# nrf54h20_engb_secure register map
Vendor: Nordic Semiconductor; Series: nRF54h; File version: 1
CPU: CM33 r0p4, little endian, MPU, no FPU, 3 interrupt priority bits, 480 interrupts, 8 SAU regions
Registers are 32-bit, read-write, reset 0x0 unless marked. A register's access mark holds for its fields unless they carry their own. Offsets are from the block's base; [hi:lo] are bit positions; lines under a group give offsets from that group; {n}, {i} and the like mark numbered series; 'fields as' and 'values as' point back to an identical list.

## SICR_S — Secure Information Configuration Registers
Base 0x0E000000
0x00 IROT group — Information on immutable Root of Trust. Secure domain ROM writes these registers only in LCS Empty, RoT and DEPLOYED.
  0x00 SYSROM group — 32-bit base revision of SysCtrl ROM and upto eight patch revisions.
    0x00 BASE — 32-bit revision of base revision of SysCtrl ROM.
      [31:0] VERSION — Base revision.
    {0x4+4k} PATCH[{k}] (k=0..7) — Description collection: 32-bit revision of utpo n patches.
      [31:0] VERSION — nth patch revision.
        0xFFFFFFFF=UnPatched (No patch applied.)
  0x24 SECROM group — 32-bit revision of Secure Domain ROM base version and utpo sixteen patch versions.
    0x00 BASE — 32-bit revision of base revision of Secure domain ROM.
      [31:0] VERSION — Base revision.
    {0x4+4k} PATCH[{k}] (k=0..15) — Description collection: 32-bit revision of utpo n patches.
      fields as IROT.SYSROM.PATCH[0]
  {0x70+4j} DEVICEID[{j}] (j=0..3) — Description collection: 128-bit UUID as Device Id.
    [0] UUID — Device UUID [n]. The DEVICE.UUID[0] contains the least significant bits of the device identifier.
  0x80 UCODE — 32-bit revision of the CRACEN uCode.
    [0] VALUE — 32-bit revision of CRACEN uCode.
  0x84 LCS1 group — LCS reported here shall be indentical to the oe in LCS2.
    0x00 LCS — The device lifecycle state as determined by the secure domain ROM code.
      [31:0] STATE — The device lifecycle state.
        0x1000=Empty (LCS is EMPTY, device assets are installed in this state.); 0x2000=RoT (Updatable RoT is installed and is verified by the immutable RoT.); 0x3000=Deployed (Similar to LCS RoT, with device certificate installed.)
  0x88 LCS2 group — LCS reported here shall be indentical to the oe in LCS1.
    0x00 LCS — The device lifecycle state as determined by the secure domain ROM code.
      fields as IROT.LCS1.LCS
  0x8C BOOTSTATUS — Indicates if the device is booted in Safe Mode.
    [31:0] STATUS — Status of boot.
      0xFFFFFFFF=NormalMode; 0xA2659BE7=Safe Mode with limited access to system resources; 0xDEB609E4=Authdbg_NormalMode (Authenticated debug session in Normal Mode.); 0xDEB67AFE=Authdbg_SafeMode (Authenticated debug session in Safe Mode.)
0xF0 UROT group — Interface to store information related to the updateable RoT.
  0x00 SM group — Signed Manifest verified by the Secure Domain ROM Code to establish the primary RoT.
    0x00 TBS group — Manifest describing the secure domain firmware. The secure domain ROM code verifies the signature on the digest of this register.
      0x00 PUBKEY group — Raw public key used to verify the signed manifest.
        0x00 SIZE — The size of the raw public key(in bytes).
          [31:0] SIZE — Key size
            0xFFFFFFFF=Unprogrammed (The key is not programmed.); 32=SizeEd25519 (The size of the raw Ed25519 public key. Currently this is the only size supported by the secure domain ROM code.)
        0x04 ADDR — Address of the raw public key.
          [31:0] ADDR — Public key address.
            0xFFFFFFFF=Unprogrammed (The key is not programmed.)
      0x08 LAYOUT group — The MRAM layout of UROT firmware and the recovery image.
        0x00 USLOT group — Start adddress and max size of UROT slot (USLOT), Shall remain the same for firmware updates once programmed or unless transitioned back to LCS Empty.
          0x00 START — Start address of the UROT firmware. Shall not overlap with the recovery slot (RSLOT).
            [31:0] ADDR
              0xFFFFFFFF=Undefined (The slot is not defined.)
          0x04 MAX — Maximum size of the UROT firmware in bytes.
            [31:0] SIZE
              0xFFFFFFFF=Undefined (The slot is not defined.)
        0x08 RSLOT group — Start adddress and max size of recovery slot (RSLOT), Shall remain the same for firmware updates once programmed or unless transitioned back to LCS Empty.
          0x00 START — Start address of the recovery firmware. Shall not overlap with the UROT slot(USLOT).
            [31:0] ADDR
              0xFFFFFFFF=Undefined (The slot is not defined.)
          0x04 MAX — Maximum size of the recovery image in bytes.
            [31:0] SIZE
              0xFFFFFFFF=Undefined (The slot is not defined.)
      0x18 FW group — FW verified by the secure domain ROM code.
        0x00 SIZE — The firmware size (in bytes). Shall not exceed the max defined limits for USLOT in case of UROT firmware.Shall not exceed the max defined limits for USLOT in case of UROT firmware.
          [31:0] SIZE — Firmware size
            0xFFFFFFFF=Unprogrammed (The FW is not programmed.)
        0x04 ADDR — Address of the firmware verified by the secure domain ROM code.
          [31:0] ADDR — Firmware address
            0xFFFFFFFF=Unprogrammed (The FW is not programmed.)
        {0x8+4m} DIGEST[{m}] (m=0..15) — Description collection: SHA2-512 digest of the firmware.
          [31:0] VALUE — SHA2-512 Digest value
            0xFFFFFFFF=Unprogrammed (The FW digest, and hence the FW is not programmed.)
        {0x48+4m} VERSION[{m}] (m=0..3) — Description collection: 128-bit revision of the firmware; can be left Unprogrammed.
          [0] VALUE — nth word of the version.
        0x58 TIMESTAMP — Unsigned 32-bit integer timestamp of the firmware in Unix time used to prevent downgrade of firmware on firmware update.
          [31:0] VALUE — Unsigned unix-time timestamp of the firmware
            0xFFFFFFFF=Unprogrammed (The FW timestamp is not programmed.)
        0x5C PARTNO — Part-number for which the firmware is built. Must match the part number in OICR region.
          [31:0] VALUE — Part number of the device for which the firmware is built.
            0xFFFFFFFF=Unprogrammed (The part number is not programmed.)
      0x78 POLICY group — Set various policies on related to the firmware verification and update.
        0x00 UPDATE — Enable or Disable firmware update.
          [31:0] ENABLE — Possible values for this register.
            0xFFFFFFFF=Unprogrammed (The policy is not programmed, hence any existing policy on update is left unchanged.); 0xC3965A5A=Enabled (Enable firmware update.); 0x47D13CA5=Disabled (Disable firmware update.)
        0x04 REVOKE — Configure key revocation policy.
          [31:0] ENABLE — Possible values for this register
            0xFFFFFFFF=Unprogrammed (The policy is not programmed, hence any existing policy on auto-revocation is left unchanged.); 0xC3965A5A=Enabled (Enable auto-revocation of keys.); 0x47D13CA5=Disabled (Disable auto-revocation of keys used to verify firmware.)
        0x08 DGPREV — Configure the downgrade prevention policy.
          [31:0] ENABLE — Possible values for this register
            0xFFFFFFFF=Unprogrammed (The policy is not programmed, hence any existing policy on downgrade prevention is unaltered.); 0xC3965A5A=Enable downgrade protection on firmware update. If Enabled, the SM.TBS.FW.TIMESTAMP register cannot be left Unprogrammed.; 0x47D13CA5=Disable downgrade protection on firmware updates. If Disabled, the SM.TBS.FW.TIMESTAMP register shall be left Unprogrammed.
        {0xC+4m} RFU[{m}] (m=0..4) — Description collection: These registers are included when generating signature of the TBS content of SM.
      {0x98+4l} CIPHERDIGEST[{l}] (l=0..15) — Description collection: SHA2-512 digest of the AES-GCM AAD, IV and encrypted firmware.
        [31:0] VALUE — SHA2-512 Digest value
          0xFFFFFFFF=Unprogrammed (Encrypted firmware digest, unprogrammed if the FW is not programmed.)
      {0xD8+4l} RFU[{l}] (l=0..3) — Description collection: These registers are included when generating signature of the TBS content of SM
    0xF4 SIGNATURE group — Signature on the manifest defined in TBS
      0x00 ALG — The signature algorithm identifier as defined in RFC8152.
        [31:0] ID — Algorithm identifier
          0xFFFFFFFF=Unprogrammed (The signature algorithm identifier is not programmed.); 5=AlgIdEd25519 (ARM ADAC-defined identifier for Ed25519. The use of ARM ADAC-defined identifier ensures consistent user interface on CTRL-AP and SICR. Only Ed25519 curve is supported.)
      0x04 SIZE — Size of the raw signature in bytes.
        [31:0] SIZE — Signature size
          0xFFFFFFFF=Unprogrammed (The signature is not programmed.); 64=SizeEd25519 (Size of Ed25519 signature bytestring.); 64=MaxSize (Currently, the secure domain ROM code supports only Ed25519 (and only Ed25519 curve) signature scheme, and hence the MaxSize is the same as the Ed25519 signature size.)
      0x08 ADDR — Address of the signature on the firmware manifest.
        [31:0] ADDR — Signature address.
          0xFFFFFFFF=Unprogrammed (The signature is not programmed.)
  0x100 RECOVERY group — Signed manifest of the recovery firmware.
    0x00 SM group — Signed Manifest verified by the Secure Domain ROM Code to establish the primary RoT.
      0x00 TBS group — Manifest describing the secure domain firmware. The secure domain ROM code verifies the signature on the digest of this register.
        0x00 PUBKEY group — Raw public key used to verify the signed manifest.
          0x00 SIZE — The size of the raw public key(in bytes).
            fields as UROT.SM.TBS.PUBKEY.SIZE
          0x04 ADDR — Address of the raw public key.
            fields as UROT.SM.TBS.PUBKEY.ADDR
        0x08 LAYOUT group — The MRAM layout of UROT firmware and the recovery image.
          0x00 USLOT group — Start adddress and max size of UROT slot (USLOT), Shall remain the same for firmware updates once programmed or unless transitioned back to LCS Empty.
            0x00 START — Start address of the UROT firmware. Shall not overlap with the recovery slot (RSLOT).
              [31:0] ADDR
                0xFFFFFFFF=Undefined (The slot is not defined.)
            0x04 MAX — Maximum size of the UROT firmware in bytes.
              [31:0] SIZE
                0xFFFFFFFF=Undefined (The slot is not defined.)
          0x08 RSLOT group — Start adddress and max size of recovery slot (RSLOT), Shall remain the same for firmware updates once programmed or unless transitioned back to LCS Empty.
            0x00 START — Start address of the recovery firmware. Shall not overlap with the UROT slot(USLOT).
              [31:0] ADDR
                0xFFFFFFFF=Undefined (The slot is not defined.)
            0x04 MAX — Maximum size of the recovery image in bytes.
              [31:0] SIZE
                0xFFFFFFFF=Undefined (The slot is not defined.)
        0x18 FW group — FW verified by the secure domain ROM code.
          0x00 SIZE — The firmware size (in bytes). Shall not exceed the max defined limits for USLOT in case of UROT firmware.Shall not exceed the max defined limits for USLOT in case of UROT firmware.
            fields as UROT.SM.TBS.FW.SIZE
          0x04 ADDR — Address of the firmware verified by the secure domain ROM code.
            fields as UROT.SM.TBS.FW.ADDR
          {0x8+4p} DIGEST[{p}] (p=0..15) — Description collection: SHA2-512 digest of the firmware.
            fields as UROT.SM.TBS.FW.DIGEST[0]
          {0x48+4p} VERSION[{p}] (p=0..3) — Description collection: 128-bit revision of the firmware; can be left Unprogrammed.
            [0] VALUE — nth word of the version.
          0x58 TIMESTAMP — Unsigned 32-bit integer timestamp of the firmware in Unix time used to prevent downgrade of firmware on firmware update.
            fields as UROT.SM.TBS.FW.TIMESTAMP
          0x5C PARTNO — Part-number for which the firmware is built. Must match the part number in OICR region.
            fields as UROT.SM.TBS.FW.PARTNO
        0x78 POLICY group — Set various policies on related to the firmware verification and update.
          0x00 UPDATE — Enable or Disable firmware update.
            fields as UROT.SM.TBS.POLICY.UPDATE
          0x04 REVOKE — Configure key revocation policy.
            fields as UROT.SM.TBS.POLICY.REVOKE
          0x08 DGPREV — Configure the downgrade prevention policy.
            fields as UROT.SM.TBS.POLICY.DGPREV
          {0xC+4p} RFU[{p}] (p=0..4) — Description collection: These registers are included when generating signature of the TBS content of SM.
        {0x98+4m} CIPHERDIGEST[{m}] (m=0..15) — Description collection: SHA2-512 digest of the AES-GCM AAD, IV and encrypted firmware.
          fields as UROT.SM.TBS.CIPHERDIGEST[0]
        {0xD8+4m} RFU[{m}] (m=0..3) — Description collection: These registers are included when generating signature of the TBS content of SM
      0xF4 SIGNATURE group — Signature on the manifest defined in TBS
        0x00 ALG — The signature algorithm identifier as defined in RFC8152.
          fields as UROT.SM.SIGNATURE.ALG
        0x04 SIZE — Size of the raw signature in bytes.
          fields as UROT.SM.SIGNATURE.SIZE
        0x08 ADDR — Address of the signature on the firmware manifest.
          fields as UROT.SM.SIGNATURE.ADDR
  0x200 UPDATE group — Description of FW Updates, if any. In case, SICR.UROT.TBS.POLICY.UPDATE is set to Disabled, these registers are ignored by the secure domain ROM code.
    0x00 OPERATION — Command from the secure domain firmware to the secure domain ROM code.
      [31:0] OPCODE — Opcode to identify the command.
        0xFFFFFFFF=Nop (No operation pending.); 0x80000001=UROTVerify (Command to only verify UROT (plain-text or encrypted) firmware update without applying it.); 0x80000002=UROTActivate (Command to verify and update encrypted UROT firmware.); 0x80000003=RecoveryVerify (Command to verify the recovery (plain-text only) firmware update without applying it.); 0x80000004=RecoveryActivate (Command to verify and update plain-text Recovery firmware.); 0x80000005=UROTPlainTextActivate (Command to verify and update plain-text UROT firmware.); 0xA0000001=AROTRecovery (Instructs the ROM code to boot the recovery image in safe mode to download a AROT image instead of a UROT image.)
    0x04 STATUS — ROM code indicates the status of update to the secure domain firmware via this register.
      [31:0] CODE — Status code.
        0xFFFFFFFF=None (No operation pending to indicate any status.); 0xF0000001=UnknownOperation (Unknown OPCODE in SICR.UROT.UPDATE.OPERATION.); 0xF0000002=InvalidManifest (The information in the manifest is invalid.); 0xF0000003=StaleFW (The timestamp on the firmware is older than the current one.); 0xF0000005=VerifyFailure (The signature did not verify.); 0xF0000006=VerifyOK (Signature verification is successful.); 0xF0000007=UROTUpdateDisabled (UROT firmware update is disabled via policy.); 0xF0000008=UROTActivated (UROT firmware update verification and installation succeeded.); 0xF0000009=RecoveryActivated (Recovery firmware update verification and installation succeeded.); 0xF000000A=RecoveryUpdateDisabled (Recovery update is disabled via policy.); 0xF1000000=AROTRecovery (Recovery image is booted so that the recovery image can download a AROT image that ROM does not verify.)
    0x08 DOWNLOAD group — Information about downloaded firmware update. The addresses described here are the location of the update and not the location they must be installed. The installation information is described in the signed manifest.
      0x00 FW — Location for the firmware update to be installed.
        [31:0] ADDR — The MRAM Location of the firmware to be installed. This is not the same as the address in the signed manifest. The signed manifest contains the target location where the firmware must be installed, not the current location where it is downloaded.
          0xFFFFFFFF=Unprogrammed (The signature is not programmed.)
      0x04 PUBKEY — Location of the public key to verify the signature on the firmware update.
        [31:0] ADDR — MRAM Location for the signature on the firmware update. This is not the same as the address in the signed manifest. The signed manifest contains the target location where the public key must be kept once the update is installed, not the current location where it is downloaded.
          0xFFFFFFFF=Unprogrammed (The signature is not programmed.)
      0x08 SIGNATURE — Location for the signature on the firmware update to be verified before the update is installed.
        [31:0] ADDR — MRAM Location for the signature on the firmware update. This is not the same as the address in the signed manifest. The signed manifest contains the target location where the signature must be kept once the update is installed, not the current location where it is downloaded.
          0xFFFFFFFF=Unprogrammed (The signature is not programmed.)
      0x0C MAX — Max Size of the download.
        [31:0] SIZE — Max size of the downloaded firmware update. This define is ignored during update of UROT or the recovery image since the signed manifest contains the needed sizes. This field is used to define the writable MRAM region when the recovery image is started in the safe mode.
          0xFFFFFFFF=Unprogrammed (The signature is not programmed.)
    0x20 SM group — Signed Manifest verified by the Secure Domain ROM Code to establish the primary RoT.
      0x00 TBS group — Manifest describing the secure domain firmware. The secure domain ROM code verifies the signature on the digest of this register.
        0x00 PUBKEY group — Raw public key used to verify the signed manifest.
          0x00 SIZE — The size of the raw public key(in bytes).
            fields as UROT.SM.TBS.PUBKEY.SIZE
          0x04 ADDR — Address of the raw public key.
            fields as UROT.SM.TBS.PUBKEY.ADDR
        0x08 LAYOUT group — The MRAM layout of UROT firmware and the recovery image.
          0x00 USLOT group — Start adddress and max size of UROT slot (USLOT), Shall remain the same for firmware updates once programmed or unless transitioned back to LCS Empty.
            0x00 START — Start address of the UROT firmware. Shall not overlap with the recovery slot (RSLOT).
              [31:0] ADDR
                0xFFFFFFFF=Undefined (The slot is not defined.)
            0x04 MAX — Maximum size of the UROT firmware in bytes.
              [31:0] SIZE
                0xFFFFFFFF=Undefined (The slot is not defined.)
          0x08 RSLOT group — Start adddress and max size of recovery slot (RSLOT), Shall remain the same for firmware updates once programmed or unless transitioned back to LCS Empty.
            0x00 START — Start address of the recovery firmware. Shall not overlap with the UROT slot(USLOT).
              [31:0] ADDR
                0xFFFFFFFF=Undefined (The slot is not defined.)
            0x04 MAX — Maximum size of the recovery image in bytes.
              [31:0] SIZE
                0xFFFFFFFF=Undefined (The slot is not defined.)
        0x18 FW group — FW verified by the secure domain ROM code.
          0x00 SIZE — The firmware size (in bytes). Shall not exceed the max defined limits for USLOT in case of UROT firmware.Shall not exceed the max defined limits for USLOT in case of UROT firmware.
            fields as UROT.SM.TBS.FW.SIZE
          0x04 ADDR — Address of the firmware verified by the secure domain ROM code.
            fields as UROT.SM.TBS.FW.ADDR
          {0x8+4p} DIGEST[{p}] (p=0..15) — Description collection: SHA2-512 digest of the firmware.
            fields as UROT.SM.TBS.FW.DIGEST[0]
          {0x48+4p} VERSION[{p}] (p=0..3) — Description collection: 128-bit revision of the firmware; can be left Unprogrammed.
            [0] VALUE — nth word of the version.
          0x58 TIMESTAMP — Unsigned 32-bit integer timestamp of the firmware in Unix time used to prevent downgrade of firmware on firmware update.
            fields as UROT.SM.TBS.FW.TIMESTAMP
          0x5C PARTNO — Part-number for which the firmware is built. Must match the part number in OICR region.
            fields as UROT.SM.TBS.FW.PARTNO
        0x78 POLICY group — Set various policies on related to the firmware verification and update.
          0x00 UPDATE — Enable or Disable firmware update.
            fields as UROT.SM.TBS.POLICY.UPDATE
          0x04 REVOKE — Configure key revocation policy.
            fields as UROT.SM.TBS.POLICY.REVOKE
          0x08 DGPREV — Configure the downgrade prevention policy.
            fields as UROT.SM.TBS.POLICY.DGPREV
          {0xC+4p} RFU[{p}] (p=0..4) — Description collection: These registers are included when generating signature of the TBS content of SM.
        {0x98+4m} CIPHERDIGEST[{m}] (m=0..15) — Description collection: SHA2-512 digest of the AES-GCM AAD, IV and encrypted firmware.
          fields as UROT.SM.TBS.CIPHERDIGEST[0]
        {0xD8+4m} RFU[{m}] (m=0..3) — Description collection: These registers are included when generating signature of the TBS content of SM
      0xF4 SIGNATURE group — Signature on the manifest defined in TBS
        0x00 ALG — The signature algorithm identifier as defined in RFC8152.
          fields as UROT.SM.SIGNATURE.ALG
        0x04 SIZE — Size of the raw signature in bytes.
          fields as UROT.SM.SIGNATURE.SIZE
        0x08 ADDR — Address of the signature on the firmware manifest.
          fields as UROT.SM.SIGNATURE.ADDR
  {0x320+4j} CERTIFICATE[{j}] (j=0..1023) — Description collection: Device X.509 certificate.
    [0] CERT — Device certificate.
0x1500 AROT group — Interface used by the secure domain firmware to extend the RoT to the other local domains and store information on configuration of debug access ports, CTRL-AP methods, and other platfrom security related configurations per domain. These registers are only accessed the secure domain firmware. Any operations related to the local domains must be requested via the secure domain firmware API.
  0x00 SECURE group — Unspecified
    {0x0+0x60*k} OEMPUBKEY[{k}] (k=0..2) group — The public key used by the top level SUIT manifest. The public key is stored as additional authenticated data (AAD) in unencrypted form using an AEAD scheme realized by AES-256 GCM mode, with the secure domain KEK used as a secret key. The initialization vector is provided in NONCE register. Key attributes from ATTR register shall be used as an additional authenticated data (AAD) in AEAD. The content of PUBKEY registers shall be used as an additional authenticated data (AAD) in AEAD.
      0x00 NONCE — Description cluster: The initialization vector of the encryption algorithm used to protect the top level SUIT manifest public key generation [n].
        [31:0] VALUE — Value of nonce used by AEAD.
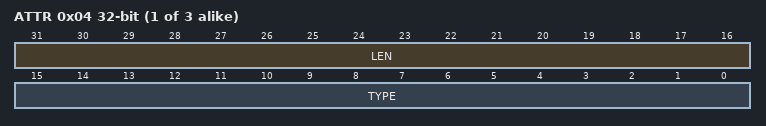
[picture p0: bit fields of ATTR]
      0x04 ATTR — Description cluster: The attributes of the local domain firmware master encryption key generation [n]. This field is used as an additional authenticated data (AAD) in AEAD.
        [31:16] LEN — Length of the key in bits.
        [15:0] TYPE — Type of the key. This field should follow the key type encoding from PSA Crypto API v1.2.1.
      {0x8+4l} PUBKEY[{l}] (l=0..15) — Description collection: The top level SUIT manifest public key generation [n]. This field is used as an additional authenticated data (AAD) in AEAD.
        [31:0] VALUE — Value for word [o] in the key value [n].
      {0x48+4l} MAC[{l}] (l=0..3) — Description collection: The authentication tag of the top level SUIT manifest public key generation [n].
        [31:0] VALUE — The word [o] of the authentication tag.
      {0x58+4l} RFU[{l}] (l=0..1) — Description collection:
        [31:0] VALUE — RFU word [o].
    0x120 PERSONALIZATION group — The device unique pad used as part of a personalization string during IKG key generation.
      {0x0+4l} PAD[{l}] (l=0..3) — Description collection: The device unique pad.
        [31:0] VALUE — Value for word [n] in the unique pad.
    0x130 DATAPROTECTION group — Elements used for validation of data provisioned onto a device by the local domain.
      0x00 UICR group — Authentication tag used for validation of the content of the UICRs. The UICRs content provides information about a domain peripherals associations and memory layout configuration. It is stored in an unencrypted form in a dedicated memory location. A validation shall be performed using an AEAD scheme realized by AES-256 GCM mode, with the domain KEK used as a secret key and UICR content used as additional authenticated data (AAD). The initialization vector is provided in NONCE register.
        0x00 NONCE — The initialization vector of the encryption algorithm used to protect the domain UICRs content.
          [31:0] VALUE — Value of nonce used by AEAD.
        {0x4+4m} MAC[{m}] (m=0..3) — Description collection: The authentication tag of the domain UICRs.
          [31:0] VALUE — The word [n] of the authentication tag.
        {0x14+4m} RFU[{m}] (m=0..2) — Description collection:
          [31:0] VALUE — RFU word [n].
  0x400 APPLICATION group — Unspecified
    {0x0+0x40*k} FWENC[{k}] (k=0..1) group — Local domain firmware master encryption key. The key is stored in an encrypted then authenticated form using an AEAD scheme realized by AES-256 GCM mode, with the local domain KEK used as a secret key. The initialization vector is provided in NONCE register. Key attributes from ATTR register shall be used as an additional authenticated data (AAD) in AEAD.
      0x00 NONCE — Description cluster: The initialization vector of the encryption algorithm used to protect the local domain firmware master encryption key generation [n].
        [31:0] VALUE — Value of nonce used by AEAD.
      0x04 ATTR — Description cluster: The attributes of the local domain firmware master encryption key generation [n]. This field is used as an additional authenticated data (AAD) in AEAD.
        fields as AROT.SECURE.OEMPUBKEY[0].ATTR
      {0x8+4l} CIPHERTEXT[{l}] (l=0..7) — Description collection: The encrypted local domain firmware master encryption key generation [n].
        [31:0] VALUE — Value for word [o] in the key value [n].
      {0x28+4l} MAC[{l}] (l=0..3) — Description collection: The authentication tag of the local domain firmware master encryption key generation [n].
        [31:0] VALUE — The word [o] of the authentication tag.
      {0x38+4l} RFU[{l}] (l=0..1) — Description collection:
        [31:0] VALUE — RFU word [o].
    {0x80+0x60*k} AUTHDEBUGKEY[{k}] (k=0..2) group — Local domain authenticated debug access public key. The public key is stored as additional authenticated data (AAD) in unencrypted form using an AEAD scheme realized by AES-256 GCM mode, with the local domain KEK used as a secret key. The initialization vector is provided in NONCE register. Key attributes from ATTR register shall be used as an additional authenticated data (AAD) in AEAD. The content of PUBKEY registers shall be used as an additional authenticated data (AAD) in AEAD.
      0x00 NONCE — Description cluster: The initialization vector of the encryption algorithm used to protect the local domain authenticated debug access public key generation [n].
        [31:0] VALUE — Value of nonce used by AEAD.
      0x04 ATTR — Description cluster: The attributes of the local domain firmware master encryption key generation [n]. This field is used as an additional authenticated data (AAD) in AEAD.
        fields as AROT.SECURE.OEMPUBKEY[0].ATTR
      {0x8+4l} PUBKEY[{l}] (l=0..15) — Description collection: The local domain authenticated debug access public key generation [n].
        [31:0] VALUE — Value for word [o] in the key value [n].
      {0x48+4l} MAC[{l}] (l=0..3) — Description collection: The authentication tag of the local domain authenticated debug access public key generation [n].
        [31:0] VALUE — The word [o] of the authentication tag.
      {0x58+4l} RFU[{l}] (l=0..1) — Description collection:
        [31:0] VALUE — RFU word [o].
    {0x1A0+0x60*k} SUITPUBKEY[{k}] (k=0..2) group — Public key used by the local domain SUIT manifest. The public key is stored as additional authenticated data (AAD) in unencrypted form using an AEAD scheme realized by AES-256 GCM mode, with the local domain KEK used as a secret key. The initialization vector is provided in NONCE register. Key attributes from ATTR register shall be used as an additional authenticated data (AAD) in AEAD. The content of PUBKEY registers shall be used as an additional authenticated data (AAD) in AEAD.
      0x00 NONCE — Description cluster: The initialization vector of the encryption algorithm used to protect the local domain SUIT manifest public key generation [n].
        [31:0] VALUE — Value of nonce used by AEAD.
      0x04 ATTR — Description cluster: The attributes of the local domain firmware master encryption key generation [n]. This field is used as an additional authenticated data (AAD) in AEAD.
        fields as AROT.SECURE.OEMPUBKEY[0].ATTR
      {0x8+4l} PUBKEY[{l}] (l=0..15) — Description collection: The local domain SUIT manifest public key generation [n].
        [31:0] VALUE — Value for word [o] in the key value [n].
      {0x48+4l} MAC[{l}] (l=0..3) — Description collection: The authentication tag of the local domain SUIT manifest public key generation [n].
        [31:0] VALUE — The word [o] of the authentication tag.
      {0x58+4l} RFU[{l}] (l=0..1) — Description collection:
        [31:0] VALUE — RFU word [o].
    0x2C0 DATAPROTECTION group — Elements used for validation of data provisioned onto a device by the local domain.
      0x00 UICR group — Authentication tag used for validation of the content of the UICRs. The UICRs content provides information about a domain peripherals associations and memory layout configuration. It is stored in an unencrypted form in a dedicated memory location. A validation shall be performed using an AEAD scheme realized by AES-256 GCM mode, with the domain KEK used as a secret key and UICR content used as additional authenticated data (AAD). The initialization vector is provided in NONCE register.
        0x00 NONCE — The initialization vector of the encryption algorithm used to protect the domain UICRs content.
          [31:0] VALUE — Value of nonce used by AEAD.
        {0x4+4m} MAC[{m}] (m=0..3) — Description collection: The authentication tag of the domain UICRs.
          [31:0] VALUE — The word [n] of the authentication tag.
        {0x14+4m} RFU[{m}] (m=0..2) — Description collection:
          [31:0] VALUE — RFU word [n].
    0x2E0 DOMAINSTATE group — Registers holding the information regarding the local domain state.
      {0x0+4l} RFU[{l}] (l=0..2) — Description collection:
        [31:0] VALUE — RFU word [n].
      0x0C LCS — The local domain lifecycle state as determined by the URoT.
        [31:0] STATE — The local domain lifecycle state.
          0x3590FCC5=AssemblyAndTest (The local domain assets are installed in this state. This includes the optional local domain ARoT (its secure program).); 0xF6852179=ARoTProvisioning (The optional local domain ARoT is provisioned in this state.); 0x9F6B5F01=Secured (The local domain assets are provisioned and secured.)
  0x800 RADIO group — Unspecified
    {0x0+0x40*k} FWENC[{k}] (k=0..1) group — Local domain firmware master encryption key. The key is stored in an encrypted then authenticated form using an AEAD scheme realized by AES-256 GCM mode, with the local domain KEK used as a secret key. The initialization vector is provided in NONCE register. Key attributes from ATTR register shall be used as an additional authenticated data (AAD) in AEAD.
      0x00 NONCE — Description cluster: The initialization vector of the encryption algorithm used to protect the local domain firmware master encryption key generation [n].
        [31:0] VALUE — Value of nonce used by AEAD.
      0x04 ATTR — Description cluster: The attributes of the local domain firmware master encryption key generation [n]. This field is used as an additional authenticated data (AAD) in AEAD.
        fields as AROT.SECURE.OEMPUBKEY[0].ATTR
      {0x8+4l} CIPHERTEXT[{l}] (l=0..7) — Description collection: The encrypted local domain firmware master encryption key generation [n].
        [31:0] VALUE — Value for word [o] in the key value [n].
      {0x28+4l} MAC[{l}] (l=0..3) — Description collection: The authentication tag of the local domain firmware master encryption key generation [n].
        [31:0] VALUE — The word [o] of the authentication tag.
      {0x38+4l} RFU[{l}] (l=0..1) — Description collection:
        [31:0] VALUE — RFU word [o].
    {0x80+0x60*k} AUTHDEBUGKEY[{k}] (k=0..2) group — Local domain authenticated debug access public key. The public key is stored as additional authenticated data (AAD) in unencrypted form using an AEAD scheme realized by AES-256 GCM mode, with the local domain KEK used as a secret key. The initialization vector is provided in NONCE register. Key attributes from ATTR register shall be used as an additional authenticated data (AAD) in AEAD. The content of PUBKEY registers shall be used as an additional authenticated data (AAD) in AEAD.
      0x00 NONCE — Description cluster: The initialization vector of the encryption algorithm used to protect the local domain authenticated debug access public key generation [n].
        [31:0] VALUE — Value of nonce used by AEAD.
      0x04 ATTR — Description cluster: The attributes of the local domain firmware master encryption key generation [n]. This field is used as an additional authenticated data (AAD) in AEAD.
        fields as AROT.SECURE.OEMPUBKEY[0].ATTR
      {0x8+4l} PUBKEY[{l}] (l=0..15) — Description collection: The local domain authenticated debug access public key generation [n].
        [31:0] VALUE — Value for word [o] in the key value [n].
      {0x48+4l} MAC[{l}] (l=0..3) — Description collection: The authentication tag of the local domain authenticated debug access public key generation [n].
        [31:0] VALUE — The word [o] of the authentication tag.
      {0x58+4l} RFU[{l}] (l=0..1) — Description collection:
        [31:0] VALUE — RFU word [o].
    {0x1A0+0x60*k} SUITPUBKEY[{k}] (k=0..2) group — Public key used by the local domain SUIT manifest. The public key is stored as additional authenticated data (AAD) in unencrypted form using an AEAD scheme realized by AES-256 GCM mode, with the local domain KEK used as a secret key. The initialization vector is provided in NONCE register. Key attributes from ATTR register shall be used as an additional authenticated data (AAD) in AEAD. The content of PUBKEY registers shall be used as an additional authenticated data (AAD) in AEAD.
      0x00 NONCE — Description cluster: The initialization vector of the encryption algorithm used to protect the local domain SUIT manifest public key generation [n].
        [31:0] VALUE — Value of nonce used by AEAD.
      0x04 ATTR — Description cluster: The attributes of the local domain firmware master encryption key generation [n]. This field is used as an additional authenticated data (AAD) in AEAD.
        fields as AROT.SECURE.OEMPUBKEY[0].ATTR
      {0x8+4l} PUBKEY[{l}] (l=0..15) — Description collection: The local domain SUIT manifest public key generation [n].
        [31:0] VALUE — Value for word [o] in the key value [n].
      {0x48+4l} MAC[{l}] (l=0..3) — Description collection: The authentication tag of the local domain SUIT manifest public key generation [n].
        [31:0] VALUE — The word [o] of the authentication tag.
      {0x58+4l} RFU[{l}] (l=0..1) — Description collection:
        [31:0] VALUE — RFU word [o].
    0x2C0 DATAPROTECTION group — Elements used for validation of data provisioned onto a device by the local domain.
      0x00 UICR group — Authentication tag used for validation of the content of the UICRs. The UICRs content provides information about a domain peripherals associations and memory layout configuration. It is stored in an unencrypted form in a dedicated memory location. A validation shall be performed using an AEAD scheme realized by AES-256 GCM mode, with the domain KEK used as a secret key and UICR content used as additional authenticated data (AAD). The initialization vector is provided in NONCE register.
        0x00 NONCE — The initialization vector of the encryption algorithm used to protect the domain UICRs content.
          [31:0] VALUE — Value of nonce used by AEAD.
        {0x4+4m} MAC[{m}] (m=0..3) — Description collection: The authentication tag of the domain UICRs.
          [31:0] VALUE — The word [n] of the authentication tag.
        {0x14+4m} RFU[{m}] (m=0..2) — Description collection:
          [31:0] VALUE — RFU word [n].
    0x2E0 DOMAINSTATE group — Registers holding the information regarding the local domain state.
      {0x0+4l} RFU[{l}] (l=0..2) — Description collection:
        [31:0] VALUE — RFU word [n].
      0x0C LCS — The local domain lifecycle state as determined by the URoT.
        fields as AROT.APPLICATION.DOMAINSTATE.LCS
  0xC00 CELLULARCORE group — Unspecified
    {0x0+0x40*k} FWENC[{k}] (k=0..1) group — Local domain firmware master encryption key. The key is stored in an encrypted then authenticated form using an AEAD scheme realized by AES-256 GCM mode, with the local domain KEK used as a secret key. The initialization vector is provided in NONCE register. Key attributes from ATTR register shall be used as an additional authenticated data (AAD) in AEAD.
      0x00 NONCE — Description cluster: The initialization vector of the encryption algorithm used to protect the local domain firmware master encryption key generation [n].
        [31:0] VALUE — Value of nonce used by AEAD.
      0x04 ATTR — Description cluster: The attributes of the local domain firmware master encryption key generation [n]. This field is used as an additional authenticated data (AAD) in AEAD.
        fields as AROT.SECURE.OEMPUBKEY[0].ATTR
      {0x8+4l} CIPHERTEXT[{l}] (l=0..7) — Description collection: The encrypted local domain firmware master encryption key generation [n].
        [31:0] VALUE — Value for word [o] in the key value [n].
      {0x28+4l} MAC[{l}] (l=0..3) — Description collection: The authentication tag of the local domain firmware master encryption key generation [n].
        [31:0] VALUE — The word [o] of the authentication tag.
      {0x38+4l} RFU[{l}] (l=0..1) — Description collection:
        [31:0] VALUE — RFU word [o].
    {0x80+0x60*k} AUTHDEBUGKEY[{k}] (k=0..2) group — Local domain authenticated debug access public key. The public key is stored as additional authenticated data (AAD) in unencrypted form using an AEAD scheme realized by AES-256 GCM mode, with the local domain KEK used as a secret key. The initialization vector is provided in NONCE register. Key attributes from ATTR register shall be used as an additional authenticated data (AAD) in AEAD. The content of PUBKEY registers shall be used as an additional authenticated data (AAD) in AEAD.
      0x00 NONCE — Description cluster: The initialization vector of the encryption algorithm used to protect the local domain authenticated debug access public key generation [n].
        [31:0] VALUE — Value of nonce used by AEAD.
      0x04 ATTR — Description cluster: The attributes of the local domain firmware master encryption key generation [n]. This field is used as an additional authenticated data (AAD) in AEAD.
        fields as AROT.SECURE.OEMPUBKEY[0].ATTR
      {0x8+4l} PUBKEY[{l}] (l=0..15) — Description collection: The local domain authenticated debug access public key generation [n].
        [31:0] VALUE — Value for word [o] in the key value [n].
      {0x48+4l} MAC[{l}] (l=0..3) — Description collection: The authentication tag of the local domain authenticated debug access public key generation [n].
        [31:0] VALUE — The word [o] of the authentication tag.
      {0x58+4l} RFU[{l}] (l=0..1) — Description collection:
        [31:0] VALUE — RFU word [o].
    {0x1A0+0x60*k} SUITPUBKEY[{k}] (k=0..2) group — Public key used by the local domain SUIT manifest. The public key is stored as additional authenticated data (AAD) in unencrypted form using an AEAD scheme realized by AES-256 GCM mode, with the local domain KEK used as a secret key. The initialization vector is provided in NONCE register. Key attributes from ATTR register shall be used as an additional authenticated data (AAD) in AEAD. The content of PUBKEY registers shall be used as an additional authenticated data (AAD) in AEAD.
      0x00 NONCE — Description cluster: The initialization vector of the encryption algorithm used to protect the local domain SUIT manifest public key generation [n].
        [31:0] VALUE — Value of nonce used by AEAD.
      0x04 ATTR — Description cluster: The attributes of the local domain firmware master encryption key generation [n]. This field is used as an additional authenticated data (AAD) in AEAD.
        fields as AROT.SECURE.OEMPUBKEY[0].ATTR
      {0x8+4l} PUBKEY[{l}] (l=0..15) — Description collection: The local domain SUIT manifest public key generation [n].
        [31:0] VALUE — Value for word [o] in the key value [n].
      {0x48+4l} MAC[{l}] (l=0..3) — Description collection: The authentication tag of the local domain SUIT manifest public key generation [n].
        [31:0] VALUE — The word [o] of the authentication tag.
      {0x58+4l} RFU[{l}] (l=0..1) — Description collection:
        [31:0] VALUE — RFU word [o].
    0x2C0 DATAPROTECTION group — Elements used for validation of data provisioned onto a device by the local domain.
      0x00 UICR group — Authentication tag used for validation of the content of the UICRs. The UICRs content provides information about a domain peripherals associations and memory layout configuration. It is stored in an unencrypted form in a dedicated memory location. A validation shall be performed using an AEAD scheme realized by AES-256 GCM mode, with the domain KEK used as a secret key and UICR content used as additional authenticated data (AAD). The initialization vector is provided in NONCE register.
        0x00 NONCE — The initialization vector of the encryption algorithm used to protect the domain UICRs content.
          [31:0] VALUE — Value of nonce used by AEAD.
        {0x4+4m} MAC[{m}] (m=0..3) — Description collection: The authentication tag of the domain UICRs.
          [31:0] VALUE — The word [n] of the authentication tag.
        {0x14+4m} RFU[{m}] (m=0..2) — Description collection:
          [31:0] VALUE — RFU word [n].
    0x2E0 DOMAINSTATE group — Registers holding the information regarding the local domain state.
      {0x0+4l} RFU[{l}] (l=0..2) — Description collection:
        [31:0] VALUE — RFU word [n].
      0x0C LCS — The local domain lifecycle state as determined by the URoT.
        fields as AROT.APPLICATION.DOMAINSTATE.LCS
  0x1000 WIFICORE group — Unspecified
    {0x0+0x40*k} FWENC[{k}] (k=0..1) group — Local domain firmware master encryption key. The key is stored in an encrypted then authenticated form using an AEAD scheme realized by AES-256 GCM mode, with the local domain KEK used as a secret key. The initialization vector is provided in NONCE register. Key attributes from ATTR register shall be used as an additional authenticated data (AAD) in AEAD.
      0x00 NONCE — Description cluster: The initialization vector of the encryption algorithm used to protect the local domain firmware master encryption key generation [n].
        [31:0] VALUE — Value of nonce used by AEAD.
      0x04 ATTR — Description cluster: The attributes of the local domain firmware master encryption key generation [n]. This field is used as an additional authenticated data (AAD) in AEAD.
        fields as AROT.SECURE.OEMPUBKEY[0].ATTR
      {0x8+4l} CIPHERTEXT[{l}] (l=0..7) — Description collection: The encrypted local domain firmware master encryption key generation [n].
        [31:0] VALUE — Value for word [o] in the key value [n].
      {0x28+4l} MAC[{l}] (l=0..3) — Description collection: The authentication tag of the local domain firmware master encryption key generation [n].
        [31:0] VALUE — The word [o] of the authentication tag.
      {0x38+4l} RFU[{l}] (l=0..1) — Description collection:
        [31:0] VALUE — RFU word [o].
    {0x80+0x60*k} AUTHDEBUGKEY[{k}] (k=0..2) group — Local domain authenticated debug access public key. The public key is stored as additional authenticated data (AAD) in unencrypted form using an AEAD scheme realized by AES-256 GCM mode, with the local domain KEK used as a secret key. The initialization vector is provided in NONCE register. Key attributes from ATTR register shall be used as an additional authenticated data (AAD) in AEAD. The content of PUBKEY registers shall be used as an additional authenticated data (AAD) in AEAD.
      0x00 NONCE — Description cluster: The initialization vector of the encryption algorithm used to protect the local domain authenticated debug access public key generation [n].
        [31:0] VALUE — Value of nonce used by AEAD.
      0x04 ATTR — Description cluster: The attributes of the local domain firmware master encryption key generation [n]. This field is used as an additional authenticated data (AAD) in AEAD.
        fields as AROT.SECURE.OEMPUBKEY[0].ATTR
      {0x8+4l} PUBKEY[{l}] (l=0..15) — Description collection: The local domain authenticated debug access public key generation [n].
        [31:0] VALUE — Value for word [o] in the key value [n].
      {0x48+4l} MAC[{l}] (l=0..3) — Description collection: The authentication tag of the local domain authenticated debug access public key generation [n].
        [31:0] VALUE — The word [o] of the authentication tag.
      {0x58+4l} RFU[{l}] (l=0..1) — Description collection:
        [31:0] VALUE — RFU word [o].
    {0x1A0+0x60*k} SUITPUBKEY[{k}] (k=0..2) group — Public key used by the local domain SUIT manifest. The public key is stored as additional authenticated data (AAD) in unencrypted form using an AEAD scheme realized by AES-256 GCM mode, with the local domain KEK used as a secret key. The initialization vector is provided in NONCE register. Key attributes from ATTR register shall be used as an additional authenticated data (AAD) in AEAD. The content of PUBKEY registers shall be used as an additional authenticated data (AAD) in AEAD.
      0x00 NONCE — Description cluster: The initialization vector of the encryption algorithm used to protect the local domain SUIT manifest public key generation [n].
        [31:0] VALUE — Value of nonce used by AEAD.
      0x04 ATTR — Description cluster: The attributes of the local domain firmware master encryption key generation [n]. This field is used as an additional authenticated data (AAD) in AEAD.
        fields as AROT.SECURE.OEMPUBKEY[0].ATTR
      {0x8+4l} PUBKEY[{l}] (l=0..15) — Description collection: The local domain SUIT manifest public key generation [n].
        [31:0] VALUE — Value for word [o] in the key value [n].
      {0x48+4l} MAC[{l}] (l=0..3) — Description collection: The authentication tag of the local domain SUIT manifest public key generation [n].
        [31:0] VALUE — The word [o] of the authentication tag.
      {0x58+4l} RFU[{l}] (l=0..1) — Description collection:
        [31:0] VALUE — RFU word [o].
    0x2C0 DATAPROTECTION group — Elements used for validation of data provisioned onto a device by the local domain.
      0x00 UICR group — Authentication tag used for validation of the content of the UICRs. The UICRs content provides information about a domain peripherals associations and memory layout configuration. It is stored in an unencrypted form in a dedicated memory location. A validation shall be performed using an AEAD scheme realized by AES-256 GCM mode, with the domain KEK used as a secret key and UICR content used as additional authenticated data (AAD). The initialization vector is provided in NONCE register.
        0x00 NONCE — The initialization vector of the encryption algorithm used to protect the domain UICRs content.
          [31:0] VALUE — Value of nonce used by AEAD.
        {0x4+4m} MAC[{m}] (m=0..3) — Description collection: The authentication tag of the domain UICRs.
          [31:0] VALUE — The word [n] of the authentication tag.
        {0x14+4m} RFU[{m}] (m=0..2) — Description collection:
          [31:0] VALUE — RFU word [n].
    0x2E0 DOMAINSTATE group — Registers holding the information regarding the local domain state.
      {0x0+4l} RFU[{l}] (l=0..2) — Description collection:
        [31:0] VALUE — RFU word [n].
      0x0C LCS — The local domain lifecycle state as determined by the URoT.
        fields as AROT.APPLICATION.DOMAINSTATE.LCS

## Notices in the file
Copyright (c) 2010 - 2024, Nordic Semiconductor ASA
All rights reserved.
Redistribution and use in source and binary forms, with or without modification,
are permitted provided that the following conditions are met:
1. Redistributions of source code must retain the above copyright notice, this
list of conditions and the following disclaimer.
2. Redistributions in binary form, except as embedded into a Nordic
Semiconductor ASA integrated circuit in a product or a software update for
such product, must reproduce the above copyright notice, this list of
conditions and the following disclaimer in the documentation and/or other
materials provided with the distribution.
3. Neither the name of Nordic Semiconductor ASA nor the names of its
contributors may be used to endorse or promote products derived from this
software without specific prior written permission.
4. This software, with or without modification, must only be used with a
Nordic Semiconductor ASA integrated circuit.
5. Any software provided in binary form under this license must not be reverse
engineered, decompiled, modified and/or disassembled.
THIS SOFTWARE IS PROVIDED BY NORDIC SEMICONDUCTOR ASA "AS IS" AND ANY EXPRESS
OR IMPLIED WARRANTIES, INCLUDING, BUT NOT LIMITED TO, THE IMPLIED WARRANTIES
OF MERCHANTABILITY, NONINFRINGEMENT, AND FITNESS FOR A PARTICULAR PURPOSE ARE
DISCLAIMED. IN NO EVENT SHALL NORDIC SEMICONDUCTOR ASA OR CONTRIBUTORS BE
LIABLE FOR ANY DIRECT, INDIRECT, INCIDENTAL, SPECIAL, EXEMPLARY, OR
CONSEQUENTIAL DAMAGES (INCLUDING, BUT NOT LIMITED TO, PROCUREMENT OF SUBSTITUTE
GOODS OR SERVICES; LOSS OF USE, DATA, OR PROFITS; OR BUSINESS INTERRUPTION)
HOWEVER CAUSED AND ON ANY THEORY OF LIABILITY, WHETHER IN CONTRACT, STRICT
LIABILITY, OR TORT (INCLUDING NEGLIGENCE OR OTHERWISE) ARISING IN ANY WAY OUT
OF THE USE OF THIS SOFTWARE, EVEN IF ADVISED OF THE POSSIBILITY OF SUCH DAMAGE.
